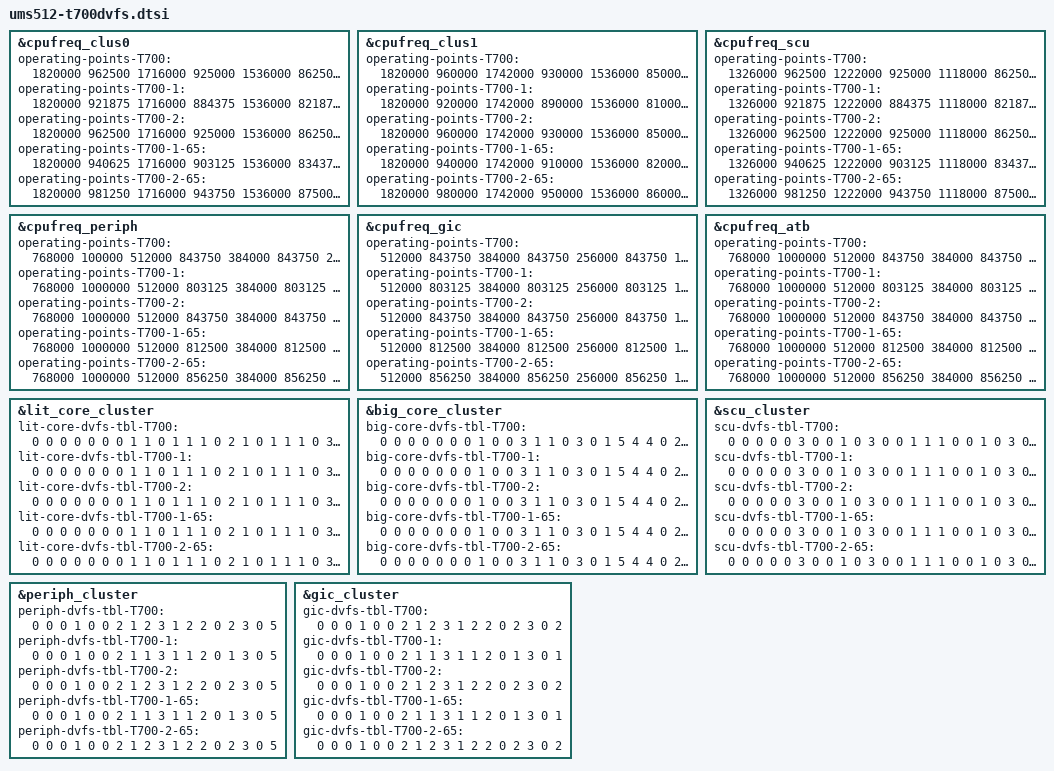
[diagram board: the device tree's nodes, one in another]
// SPDX-License-Identifier: (GPL-2.0+ OR MIT)
/*
 * Unisoc Sharkl5Pro platform T700 SOC DVFS DTS file
 *
 * Copyright (C) 2020, Unisoc Communications Inc.
 */

#include "sharkl5Pro.dtsi"
#include "ums512.dtsi"

&cpufreq_clus0 {
	/* operating-points-T700-0-0
	 * T700-soc_ver 0-binning 0-temp
	 */
	operating-points-T700 = <
		/* kHZ   uV */
		1820000 962500
		1716000 925000
		1536000 862500
		1482000 843750
		1228800 756250
		1144000 750000
		962000  750000
		768000  750000
		614400  750000
	>;

	operating-points-T700-1 = <
		/* kHZ   uV */
		1820000 921875
		1716000 884375
		1536000 821875
		1482000 803125
		1228800 750000
		1144000 750000
		962000  750000
		768000  750000
		614400  750000
	>;

	operating-points-T700-2 = <
		/* kHZ   uV */
		1820000 962500
		1716000 925000
		1536000 862500
		1482000 843750
		1228800 756250
		1144000 750000
		962000  750000
		768000  750000
		614400  750000
	>;

	operating-points-T700-1-65 = <
		/* kHZ   uV */
		1820000 940625
		1716000 903125
		1536000 834375
		1482000 812500
		1228800 750000
		1144000 750000
		962000  750000
		768000  750000
		614400  750000
	>;

	operating-points-T700-2-65 = <
		/* kHZ   uV */
		1820000 981250
		1716000 943750
		1536000 875000
		1482000 856250
		1228800 759375
		1144000 750000
		962000  750000
		768000  750000
		614400  750000
	>;
};

&cpufreq_clus1 {
	operating-points-T700 = <
		/* kHZ   uV */
		1820000 960000
		1742000 930000
		1536000	850000
		1482000	830000
		1228800	750000
	>;

	operating-points-T700-1 = <
		/* kHZ   uV */
		1820000 920000
		1742000 890000
		1536000	810000
		1482000	790000
		1228800	750000
	>;

	operating-points-T700-2 = <
		/* kHZ   uV */
		1820000 960000
		1742000 930000
		1536000	850000
		1482000	830000
		1228800	750000
	>;

	operating-points-T700-1-65 = <
		/* kHZ   uV */
		1820000 940000
		1742000 910000
		1536000	820000
		1482000	800000
		1228800	750000
	>;

	operating-points-T700-2-65 = <
		/* kHZ   uV */
		1820000 980000
		1742000 950000
		1536000	860000
		1482000	840000
		1228800	750000
	>;
};

&cpufreq_scu {
	operating-points-T700 = <
		/* kHz   uV */
		1326000 962500
		1222000 925000
		1118000 862500
		1014000 843750
		962000  756250
		768000  750000
		650000  750000
		546000  750000
	>;

	operating-points-T700-1 = <
		/* kHz   uV */
		1326000 921875
		1222000 884375
		1118000 821875
		1014000 803125
		962000  750000
		768000  750000
		650000  750000
		546000  750000
	>;

	operating-points-T700-2 = <
		/* kHz   uV */
		1326000 962500
		1222000 925000
		1118000 862500
		1014000 843750
		962000  756250
		768000  750000
		650000  750000
		546000  750000
	>;

	operating-points-T700-1-65 = <
		/* kHz   uV */
		1326000 940625
		1222000 903125
		1118000 834375
		1014000 812500
		962000  750000
		768000  750000
		650000  750000
		546000  750000
	>;

	operating-points-T700-2-65 = <
		/* kHz   uV */
		1326000 981250
		1222000 943750
		1118000 875000
		1014000 856250
		962000  759375
		768000  750000
		650000  750000
		546000  750000
	>;
};

&cpufreq_periph {
	operating-points-T700 = <
		/* kHZ  uV */
		768000 100000
		512000 843750
		384000 843750
		256000 843750
		153600 750000
	>;

	operating-points-T700-1 = <
		/* kHZ  uV */
		768000 1000000
		512000 803125
		384000 803125
		256000 803125
		153600 750000
	>;

	operating-points-T700-2 = <
		/* kHZ  uV */
		768000 1000000
		512000 843750
		384000 843750
		256000 843750
		153600 750000
	>;

	operating-points-T700-1-65 = <
		/* kHZ  uV */
		768000 1000000
		512000 812500
		384000 812500
		256000 812500
		153600 750000
	>;

	operating-points-T700-2-65 = <
		/* kHZ  uV */
		768000 1000000
		512000 856250
		384000 856250
		256000 856250
		153600 750000
	>;
};

&cpufreq_gic {
	operating-points-T700 = <
		/* kHZ  uV */
		512000 843750
		384000 843750
		256000 843750
		192000 843750
		153600 750000
	>;

	operating-points-T700-1 = <
		/* kHZ  uV */
		512000 803125
		384000 803125
		256000 803125
		192000 803125
		153600 750000
	>;

	operating-points-T700-2 = <
		/* kHZ  uV */
		512000 843750
		384000 843750
		256000 843750
		192000 843750
		153600 750000
	>;

	operating-points-T700-1-65 = <
		/* kHZ  uV */
		512000 812500
		384000 812500
		256000 812500
		192000 812500
		153600 750000
	>;

	operating-points-T700-2-65 = <
		/* kHZ  uV */
		512000 856250
		384000 856250
		256000 856250
		192000 856250
		153600 750000
	>;
};

&cpufreq_atb {
	operating-points-T700 = <
		/* kHZ  uV */
		768000 1000000
		512000 843750
		384000 843750
		256000 750000
		153600 750000
	>;

	operating-points-T700-1 = <
		/* kHZ  uV */
		768000 1000000
		512000 803125
		384000 803125
		256000 750000
		153600 750000
	>;

	operating-points-T700-2 = <
		/* kHZ  uV */
		768000 1000000
		512000 843750
		384000 843750
		256000 750000
		153600 750000
	>;

	operating-points-T700-1-65 = <
		/* kHZ  uV */
		768000 1000000
		512000 812500
		384000 812500
		256000 750000
		153600 750000
	>;

	operating-points-T700-2-65 = <
		/* kHZ  uV */
		768000 1000000
		512000 856250
		384000 856250
		256000 750000
		153600 750000
	>;
};

&lit_core_cluster{
	/* lit-core-dvfs-tbl-T700-0-0
	 * T700-soc_ver 0-binning 0-temp
	 * sel, div, vol, vote_scu, vote_peri, vote_gic, mpllx
	 */
	lit-core-dvfs-tbl-T700 = <
		0 0 0 0 0 0 0
		1 1 0 1 1 1 0
		2 1 0 1 1 1 0
		3 0 0 2 1 1 0
		3 0 0 3 1 1 1
		1 0 1 4 1 1 0
		3 0 2 5 4 4 2
		2 0 3 6 4 4 0
		3 0 4 7 4 5 3
		3 0 5 8 4 5 4
		3 0 5 8 4 5 4
	>;

	lit-core-dvfs-tbl-T700-1 = <
		0 0 0 0 0 0 0
		1 1 0 1 1 1 0
		2 1 0 1 1 1 0
		3 0 0 2 1 1 0
		3 0 0 3 1 1 1
		1 0 0 4 1 1 0
		3 0 1 5 4 4 2
		2 0 2 6 4 4 0
		3 0 3 7 4 5 3
		3 0 4 8 4 5 4
		3 0 4 8 4 5 4
	>;

	lit-core-dvfs-tbl-T700-2 = <
		0 0 0 0 0 0 0
		1 1 0 1 1 1 0
		2 1 0 1 1 1 0
		3 0 0 2 1 1 0
		3 0 0 3 1 1 1
		1 0 1 4 1 1 0
		3 0 2 5 4 4 2
		2 0 3 6 4 4 0
		3 0 4 7 4 5 3
		3 0 5 8 4 5 4
		3 0 5 8 4 5 4
	>;

	lit-core-dvfs-tbl-T700-1-65 = <
		0 0 0 0 0 0 0
		1 1 0 1 1 1 0
		2 1 0 1 1 1 0
		3 0 0 2 1 1 0
		3 0 0 3 1 1 1
		1 0 0 4 1 1 0
		3 0 1 5 4 4 2
		2 0 2 6 4 4 0
		3 0 3 7 4 5 3
		3 0 4 8 4 5 4
		3 0 4 8 4 5 4
	>;

	lit-core-dvfs-tbl-T700-2-65 = <
		0 0 0 0 0 0 0
		1 1 0 1 1 1 0
		2 1 0 1 1 1 0
		3 0 0 2 1 1 0
		3 0 0 3 1 1 1
		1 0 1 4 1 1 0
		3 0 2 5 4 4 2
		2 0 3 6 4 4 0
		3 0 4 7 4 5 3
		3 0 5 8 4 5 4
		3 0 5 8 4 5 4
	>;
};

&big_core_cluster {
	/* sel, div, vol, vote_scu, vote_peri, vote_gic, mpllx */
	big-core-dvfs-tbl-T700 = <
		0 0 0 0 0 0 0
		1 0 0 3 1 1 0
		3 0 1 5 4 4 0
		2 0 2 6 4 4 0
		3 0 3 7 4 5 1
		3 0 4 8 4 5 2
		3 0 4 8 4 5 2
	>;

	big-core-dvfs-tbl-T700-1 = <
		0 0 0 0 0 0 0
		1 0 0 3 1 1 0
		3 0 1 5 4 4 0
		2 0 2 6 4 4 0
		3 0 3 7 4 5 1
		3 0 4 8 4 5 2
		3 0 4 8 4 5 2
	>;

	big-core-dvfs-tbl-T700-2 = <
		0 0 0 0 0 0 0
		1 0 0 3 1 1 0
		3 0 1 5 4 4 0
		2 0 2 6 4 4 0
		3 0 3 7 4 5 1
		3 0 4 8 4 5 2
		3 0 4 8 4 5 2
	>;

	big-core-dvfs-tbl-T700-1-65 = <
		0 0 0 0 0 0 0
		1 0 0 3 1 1 0
		3 0 1 5 4 4 0
		2 0 2 6 4 4 0
		3 0 3 7 4 5 1
		3 0 4 8 4 5 2
		3 0 4 8 4 5 2
	>;

	big-core-dvfs-tbl-T700-2-65 = <
		0 0 0 0 0 0 0
		1 0 0 3 1 1 0
		3 0 1 5 4 4 0
		2 0 2 6 4 4 0
		3 0 3 7 4 5 1
		3 0 4 8 4 5 2
		3 0 4 8 4 5 2
	>;
};

&scu_cluster {
	/* sel div vol ace_div mpllx */
	scu-dvfs-tbl-T700 = <
		0 0 0 0 0
		3 0 0 1 0
		3 0 0 1 1
		1 0 0 1 0
		3 0 1 1 2
		3 0 2 1 3
		3 0 3 1 4
		3 0 4 1 5
		3 0 5 1 6
		3 0 5 1 6
	>;

	scu-dvfs-tbl-T700-1 = <
		0 0 0 0 0
		3 0 0 1 0
		3 0 0 1 1
		1 0 0 1 0
		3 0 0 1 2
		3 0 0 1 3
		3 0 1 1 4
		3 0 2 1 5
		3 0 3 1 6
		3 0 4 1 6
	>;

	scu-dvfs-tbl-T700-2 = <
		0 0 0 0 0
		3 0 0 1 0
		3 0 0 1 1
		1 0 0 1 0
		3 0 0 1 2
		3 0 1 1 3
		3 0 2 1 4
		3 0 3 1 5
		3 0 4 1 6
		3 0 5 1 6
	>;

	scu-dvfs-tbl-T700-1-65 = <
		0 0 0 0 0
		3 0 0 1 0
		3 0 0 1 1
		1 0 0 1 0
		3 0 0 1 2
		3 0 0 1 3
		3 0 1 1 4
		3 0 2 1 5
		3 0 3 1 6
		3 0 4 1 6
	>;

	scu-dvfs-tbl-T700-2-65 = <
		0 0 0 0 0
		3 0 0 1 0
		3 0 0 1 1
		1 0 0 1 0
		3 0 0 1 2
		3 0 1 1 3
		3 0 2 1 4
		3 0 3 1 5
		3 0 4 1 6
		3 0 5 1 6
	>;
};

&periph_cluster{
	/* sel div vol */
	periph-dvfs-tbl-T700 = <
		0 0 0
		1 0 0
		2 1 2
		3 1 2
		2 0 2
		3 0 5
	>;

	periph-dvfs-tbl-T700-1 = <
		0 0 0
		1 0 0
		2 1 1
		3 1 1
		2 0 1
		3 0 5
	>;

	periph-dvfs-tbl-T700-2 = <
		0 0 0
		1 0 0
		2 1 2
		3 1 2
		2 0 2
		3 0 5
	>;

	periph-dvfs-tbl-T700-1-65 = <
		0 0 0
		1 0 0
		2 1 1
		3 1 1
		2 0 1
		3 0 5
	>;

	periph-dvfs-tbl-T700-2-65 = <
		0 0 0
		1 0 0
		2 1 2
		3 1 2
		2 0 2
		3 0 5
	>;
};

&gic_cluster {
	/*sel div vol*/
	gic-dvfs-tbl-T700 = <
		0 0 0
		1 0 0
		2 1 2
		3 1 2
		2 0 2
		3 0 2
	>;

	gic-dvfs-tbl-T700-1 = <
		0 0 0
		1 0 0
		2 1 1
		3 1 1
		2 0 1
		3 0 1
	>;

	gic-dvfs-tbl-T700-2 = <
		0 0 0
		1 0 0
		2 1 2
		3 1 2
		2 0 2
		3 0 2
	>;

	gic-dvfs-tbl-T700-1-65 = <
		0 0 0
		1 0 0
		2 1 1
		3 1 1
		2 0 1
		3 0 1
	>;

	gic-dvfs-tbl-T700-2-65 = <
		0 0 0
		1 0 0
		2 1 2
		3 1 2
		2 0 2
		3 0 2
	>;
};
